# nrf9230_secure register map
Vendor: Nordic Semiconductor; Series: nRF92; File version: 1
CPU: CM33 r0p4, little endian, MPU, no FPU, 3 interrupt priority bits, 480 interrupts, 8 SAU regions
Registers are 32-bit, read-write, reset 0x0 unless marked. A register's access mark holds for its fields unless they carry their own. Offsets are from the block's base; [hi:lo] are bit positions; lines under a group give offsets from that group; {n}, {i} and the like mark numbered series.

## PCGCS000_NS — PCGCSlave 0
Base 0x5100A000
Same registers: PCGCS000_S 0x5100A000 (alternate view of PCGCS000_NS), PCGCS010_NS 0x5101A000, PCGCS010_S 0x5101A000 (alternate view of PCGCS010_NS)
{0xC00+4i} PENALTY[{i}] (i=0..1) reset 0xFFFFFFFC — Description collection: Penalty level for power/clock pair n. When FULL_PCP_ZERO feature is not supported, PENALTY[0] address overlaps the PENALTY0 address and register description for PENALTY[0] is not valid.
  [1:0] PENALTY — Penalty level
0xC00 PENALTY0 (alternate view of PENALTY[*]) — Penalty level for power/clock pair 0. The register description is valid only when FULL_PCP_ZERO feature is not supported
  [1:0] PENALTY ro — Penalty level
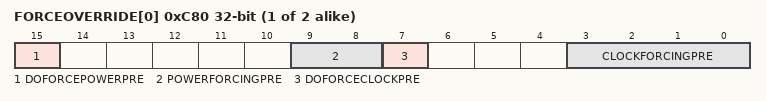
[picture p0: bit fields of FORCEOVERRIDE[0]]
{0xC80+4i} FORCEOVERRIDE[{i}] (i=0..1) — Description collection: Force override of power/clock pair n.
  [15] DOFORCEPOWERPRE, [9:8] POWERFORCINGPRE, [7] DOFORCECLOCKPRE, [3:0] CLOCKFORCINGPRE

## PCGCM000_S — PCGC Master 0
Base 0x5100B000
Same registers: PCGCM001_NS 0x5100F000, PCGCM001_S 0x5100F000 (alternate view of PCGCM001_NS), PCGCM010_S 0x5101B000, PCGCM011_NS 0x5101F000, PCGCM011_S 0x5101F000 (alternate view of PCGCM011_NS)
{0xE0+4i} SETPWRCONTHRESHOLDBASE[{i}] (i=0..2) — Description collection: Set power consumption threshold base for power source / regulator n
  [3:0] SETPWRCONTHRESHOLDBASE
0xC00 UNLOCKBACKDOORS
  [15:0] UNLOCKBACKDOORS — Write: 0x00009375 to lock/unlock backdoors Read: 0x00000001 if backdoors is enabled Read: 0x00000000 if backdoors is disabled
0xC04 ENABLEPOWERREGFORCE
  [2:0] ENABLEPOWERREGFORCE
0xC08 POWERREGFORCE — Force reg
  [2:0] POWERREGFORCEREG
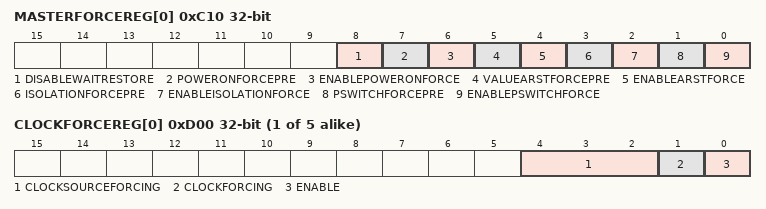
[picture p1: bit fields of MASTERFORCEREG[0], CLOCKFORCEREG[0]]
{0xC10+4i} MASTERFORCEREG[{i}] (i=0..0) — Description collection: Force reg
  [8] DISABLEWAITRESTORE — Turn off waiting for arst deactivation before retention restore
    1=Disable (Turn off waiting for arst deactivation before retention restore); 0=Enable (Wait for arst deactivation before retention restore)
  [7] POWERONFORCEPRE
  [6] ENABLEPOWERONFORCE
  [5] VALUEARSTFORCEPRE
  [4] ENABLEARSTFORCE
  [3] ISOLATIONFORCEPRE
  [2] ENABLEISOLATIONFORCE
  [1] PSWITCHFORCEPRE
  [0] ENABLEPSWITCHFORCE
{0xD00+4i} CLOCKFORCEREG[{i}] (i=0..4) — Description collection: Force clock n
  [4:2] CLOCKSOURCEFORCING
  [1] CLOCKFORCING
  [0] ENABLE — Enable clock forcing

## CPUCONF_NS — CPU Configuration 0
Base 0x41011000
Same registers: CPUCONF_S 0x51011000
0x00 TASKS_ERASECACHE wo — Erase the caches used by the CPU.
  [0] TASKS_ERASECACHE
    1=Trigger task
0x500 INITSVTOR reset 0x1000000 — Initial value of the secure VTOR (Vector Table Offset Register) after CPU reset.
  [31:0] INITSVTOR — Initial value of the VTOR.
0x504 INITNSVTOR reset 0x1000000 — Initial value of the non-secure VTOR (Vector Table Offset Register).
  [31:0] INITNSVTOR — Initial value of the VTOR.
0x508 CPUSTART reset 0x1 — Enable for starting the CPU
  [0] EN — Enable to start the CPU.
    0=Stopped (CPU stopped.); 1=Started (CPU started.)
0x50C CPUWAIT — Enable for the CPU wait.
  [0] EN — Enable to the CPU wait.
    0=Disabled (CPU is not waiting.); 1=Enabled (CPU is waiting.)

## MUTEX_NS — MUTEX 0
Base 0x41017000
Same registers: MUTEX_S 0x51017000
{0x400+4i} MUTEX[{i}] (i=0..7) — Description collection: Mutex register
  [0] MUTEX — Mutex register n
    0=Unlocked (Mutex n is in unlocked state); 1=Locked (Mutex n is in locked state)

## RESETINFO_S — RESETINFO
Base 0x5101E000; alternate view of LRCCONF010_NS
0x4A0 RESETREAS group — Unspecified
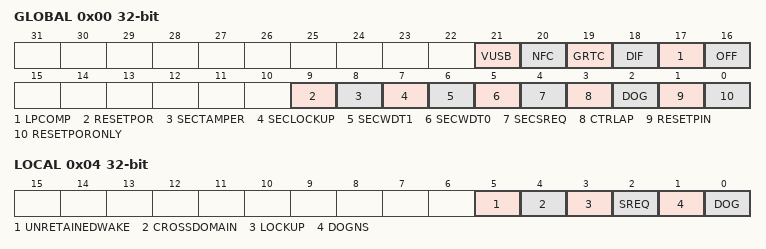
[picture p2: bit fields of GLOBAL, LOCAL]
  0x00 GLOBAL — Global reset reason.
    [all] fields
      0=NotDetected; 1=Detected
    [21] VUSB — Reset after wakeup from System OFF mode due to VBUS rising into valid range.
    [20] NFC — Reset due to wakeup from System OFF mode when wakeup is triggered by NFC field detection in sense mode.
    [19] GRTC — Reset due to wakeup from System OFF mode when wakeup is triggered by GRTC interrupt.
    [18] DIF — Reset due to wakeup from System OFF mode when wakeup is triggered by entering the debug interface mode.
    [17] LPCOMP — Reset due to wakeup from System OFF mode when wakeup is triggered by LPCOMP (Low Power Comparator).
    [16] OFF — Reset due to wakeup from System OFF mode when wakeup is triggered by DETECT signal from GPIO.
    [9] RESETPOR — Reset from power on reset (reset reason other than POR or BOR).
    [8] SECTAMPER — Reset due to secure domain tamper detected
    [7] SECLOCKUP — Reset due to secure domain lockup.
    [6] SECWDT1 — Reset due to the second instance of watchdog timer in secure domain detected.
    [5] SECWDT0 — Reset due to the first instance of watchdog timer in secure domain detected.
    [4] SECSREQ — Reset due to secure domain system reset request.
    [3] CTRLAP — Reset from CTRL-AP detected.
    [2] DOG — Reset from the SysCtrl watchdog timer detected.
    [1] RESETPIN — Reset from pin reset detected.
    [0] RESETPORONLY — Reset from power on reset (reset reason POR or BOR).
  0x04 LOCAL — Local reset reason.
    [5] UNRETAINEDWAKE — Reset due to wake from unretained state.
    [4] CROSSDOMAIN — Reset due to cross domain reset source.
      0=NotDetected; 1=Detected
    [3] LOCKUP — Reset from local CPU lockup detected
      0=NotDetected; 1=Detected
    [2] SREQ — Reset from the local soft reset request detected.
      0=NotDetected; 1=Detected
    [1] DOGNS — Reset from the local non-secure watchdog timer detected
      0=NotDetected; 1=Detected
    [0] DOG — Reset from the local watchdog timer detected
      0=NotDetected; 1=Detected
0x4A8 ERROR group — Unspecified
  0x00 STATUS — Reset error status.
    [3:0] ERRORSTATUS
  0x04 ADDRESS — Reset error address.
    [31:0] ERRORADDRESS
0x4C0 RESTOREVALID — Valid restore image is present in RAM.
  [0] RESTOREVALID
    0=NotPreset (Not present); 1=Present
0x4C4 MASKLOCKUP — Mask CPU lockup signal.
  [0] MASK — Mask lockup signal
    0=NotMask (Do not mask lockup signal); 1=Mask lockup signal

## Notices in the file
Copyright (c) 2010 - 2024, Nordic Semiconductor ASA
All rights reserved.
Redistribution and use in source and binary forms, with or without modification,
are permitted provided that the following conditions are met:
1. Redistributions of source code must retain the above copyright notice, this
list of conditions and the following disclaimer.
2. Redistributions in binary form, except as embedded into a Nordic
Semiconductor ASA integrated circuit in a product or a software update for
such product, must reproduce the above copyright notice, this list of
conditions and the following disclaimer in the documentation and/or other
materials provided with the distribution.
3. Neither the name of Nordic Semiconductor ASA nor the names of its
contributors may be used to endorse or promote products derived from this
software without specific prior written permission.
4. This software, with or without modification, must only be used with a
Nordic Semiconductor ASA integrated circuit.
5. Any software provided in binary form under this license must not be reverse
engineered, decompiled, modified and/or disassembled.
THIS SOFTWARE IS PROVIDED BY NORDIC SEMICONDUCTOR ASA "AS IS" AND ANY EXPRESS
OR IMPLIED WARRANTIES, INCLUDING, BUT NOT LIMITED TO, THE IMPLIED WARRANTIES
OF MERCHANTABILITY, NONINFRINGEMENT, AND FITNESS FOR A PARTICULAR PURPOSE ARE
DISCLAIMED. IN NO EVENT SHALL NORDIC SEMICONDUCTOR ASA OR CONTRIBUTORS BE
LIABLE FOR ANY DIRECT, INDIRECT, INCIDENTAL, SPECIAL, EXEMPLARY, OR
CONSEQUENTIAL DAMAGES (INCLUDING, BUT NOT LIMITED TO, PROCUREMENT OF SUBSTITUTE
GOODS OR SERVICES; LOSS OF USE, DATA, OR PROFITS; OR BUSINESS INTERRUPTION)
HOWEVER CAUSED AND ON ANY THEORY OF LIABILITY, WHETHER IN CONTRACT, STRICT
LIABILITY, OR TORT (INCLUDING NEGLIGENCE OR OTHERWISE) ARISING IN ANY WAY OUT
OF THE USE OF THIS SOFTWARE, EVEN IF ADVISED OF THE POSSIBILITY OF SUCH DAMAGE.
